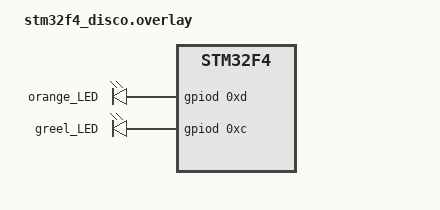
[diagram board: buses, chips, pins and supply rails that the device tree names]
/{
	leds{
		orange_led: led0{
			gpios = <&gpiod 0xd 0>;
			label = "orange_LED";
		};

		green_led: led1{
			gpios = <&gpiod 0xc 0>;
			label = "greel_LED";
		};
	};

	aliases{
		orange-led = &orange_led;
	};
};
